# ATSAM4E16C device description
Architecture: CORTEX-M4; Family: SAM4; Series: SAM4E
Registers are 32-bit, read-write, no defined reset value unless marked. A register's access mark holds for its fields unless they carry their own. Offsets are from the block's base; [hi:lo] are bit positions; {n}, {i} and the like mark numbered series.

## ACC — Analog Comparator Controller
Instances: ACC 0x400BC000
0x00 ACC_CR wo — Control Register
  [0] SWRST — SoftWare ReSeT
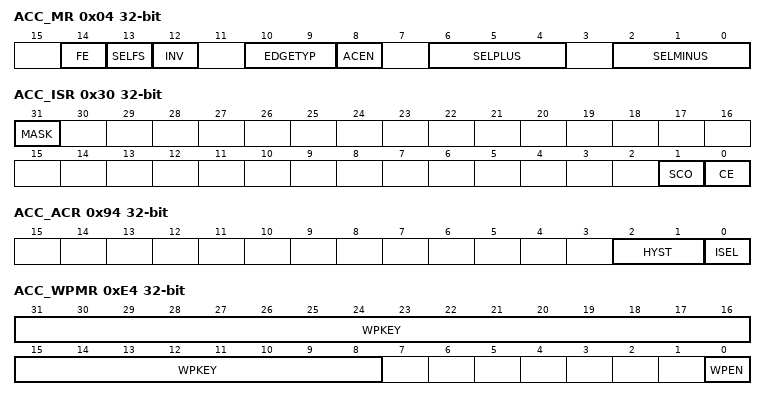
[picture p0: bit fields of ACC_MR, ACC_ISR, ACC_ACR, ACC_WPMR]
0x04 ACC_MR — Mode Register
  [14] FE — Fault Enable
    0=DIS (the FAULT output is tied to 0.); 1=EN (the FAULT output is driven by the signal defined by SELFS.)
  [13] SELFS — SELection of Fault Source
    0=CF (the CF flag is used to drive the FAULT output.); 1=OUTPUT (the output of the Analog Comparator flag is used to drive the FAULT output.)
  [12] INV — INVert comparator output
    0=DIS (Analog Comparator output is directly processed.); 1=EN (Analog Comparator output is inverted prior to being processed.)
  [10:9] EDGETYP — EDGE TYPe
    0=RISING (only rising edge of comparator output); 1=FALLING (falling edge of comparator output); 2=ANY (any edge of comparator output)
  [8] ACEN — Analog Comparator ENable
    0=DIS (Analog Comparator Disabled.); 1=EN (Analog Comparator Enabled.)
  [6:4] SELPLUS — SELection for PLUS comparator input
    {v}=AD{v} (Select AD{v}) (v=0..7)
  [2:0] SELMINUS — SELection for MINUS comparator input
    0=TS (SelectTS); 1=ADVREF (Select ADVREF); 2=DAC0 (Select DAC0); 3=DAC1 (Select DAC1); {v}=AD{v-4} (Select AD{v-4}) (v=4..7)
0x24 ACC_IER wo — Interrupt Enable Register
  [0] CE — Comparison Edge
0x28 ACC_IDR wo — Interrupt Disable Register
  [0] CE — Comparison Edge
0x2C ACC_IMR ro — Interrupt Mask Register
  [0] CE — Comparison Edge
0x30 ACC_ISR ro — Interrupt Status Register
  [31] MASK
  [1] SCO — Synchronized Comparator Output
  [0] CE — Comparison Edge
0x94 ACC_ACR — Analog Control Register
  [2:1] HYST — HYSTeresis selection
  [0] ISEL — Current SELection
    0=LOPW (low power option.); 1=HISP (high speed option.)
0xE4 ACC_WPMR — Write Protect Mode Register
  [31:8] WPKEY — Write Protect KEY
  [0] WPEN — Write Protect Enable
0xE8 ACC_WPSR ro — Write Protect Status Register
  [0] WPROTERR — Write PROTection ERRor

## AES — Advanced Encryption Standard
Instances: AES 0x40004000
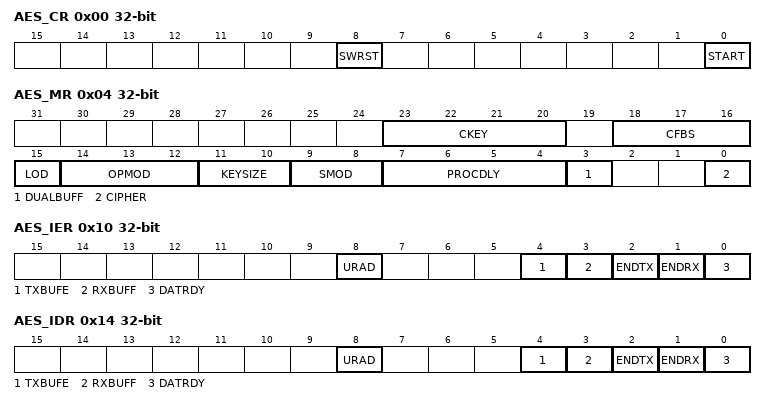
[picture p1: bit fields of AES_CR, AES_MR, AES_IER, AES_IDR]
0x00 AES_CR wo — Control Register
  [8] SWRST — Software Reset
  [0] START — Start Processing
0x04 AES_MR — Mode Register
  [23:20] CKEY — Key
  [18:16] CFBS — Cipher Feedback Data Size
    0=SIZE_128BIT (128-bit); 1=SIZE_64BIT (64-bit); 2=SIZE_32BIT (32-bit); 3=SIZE_16BIT (16-bit); 4=SIZE_8BIT (8-bit)
  [15] LOD — Last Output Data Mode
  [14:12] OPMOD — Operation Mode
    0=ECB (ECB: Electronic Code Book mode); 1=CBC (CBC: Cipher Block Chaining mode); 2=OFB (OFB: Output Feedback mode); 3=CFB (CFB: Cipher Feedback mode); 4=CTR (CTR: Counter mode (16-bit internal counter))
  [11:10] KEYSIZE
    0=AES128 (AES Key Size is 128 bits); 1=AES192 (AES Key Size is 192 bits); 2=AES256 (AES Key Size is 256 bits)
  [9:8] SMOD — Start Mode
    0=MANUAL_START (Manual Mode); 1=AUTO_START (Auto Mode); 2=IDATAR0_START (AES_IDATAR0 access only Auto Mode)
  [7:4] PROCDLY — Processing Delay
  [3] DUALBUFF — Dual Input BUFFer
    0=INACTIVE (AES_IDATARx cannot be written during processing of previous block.); 1=ACTIVE (AES_IDATARx can be written during processing of previous block when SMOD = 0x2. It speeds up the overall runtime of large files.)
  [0] CIPHER — Processing Mode
0x10 AES_IER wo — Interrupt Enable Register
  [8] URAD — Unspecified Register Access Detection Interrupt Enable
  [4] TXBUFE — Transmit Buffer Empty Interrupt Enable
  [3] RXBUFF — Receive Buffer Full Interrupt Enable
  [2] ENDTX — End of Transmit Buffer Interrupt Enable
  [1] ENDRX — End of Receive Buffer Interrupt Enable
  [0] DATRDY — Data Ready Interrupt Enable
0x14 AES_IDR wo — Interrupt Disable Register
  [8] URAD — Unspecified Register Access Detection Interrupt Disable
  [4] TXBUFE — Transmit Buffer Empty Interrupt Disable
  [3] RXBUFF — Receive Buffer Full Interrupt Disable
  [2] ENDTX — End of Transmit Buffer Interrupt Disable
  [1] ENDRX — End of Receive Buffer Interrupt Disable
  [0] DATRDY — Data Ready Interrupt Disable
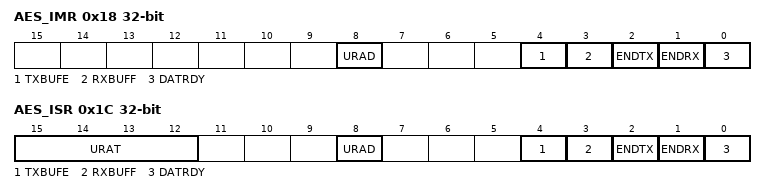
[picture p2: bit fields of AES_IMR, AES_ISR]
0x18 AES_IMR ro — Interrupt Mask Register
  [8] URAD — Unspecified Register Access Detection Interrupt Mask
  [4] TXBUFE — Transmit Buffer Empty Interrupt Mask
  [3] RXBUFF — Receive Buffer Full Interrupt Mask
  [2] ENDTX — End of Transmit Buffer Interrupt Mask
  [1] ENDRX — End of Receive Buffer Interrupt Mask
  [0] DATRDY — Data Ready Interrupt Mask
0x1C AES_ISR ro — Interrupt Status Register
  [15:12] URAT — Unspecified Register Access:
    0=IDR_WR_PROCESSING (Input Data Register written during the data processing when SMOD=0x2 mode.); 1=ODR_RD_PROCESSING (Output Data Register read during the data processing.); 2=MR_WR_PROCESSING (Mode Register written during the data processing.); 3=ODR_RD_SUBKGEN (Output Data Register read during the sub-keys generation.); 4=MR_WR_SUBKGEN (Mode Register written during the sub-keys generation.); 5=WOR_RD_ACCESS (Write-only register read access.)
  [8] URAD — Unspecified Register Access Detection Status
  [4] TXBUFE — TX Buffer Empty
  [3] RXBUFF — RX Buffer Full
  [2] ENDTX — End of TX Buffer
  [1] ENDRX — End of RX Buffer
  [0] DATRDY — Data Ready
{0x20+4i} AES_KEYWR{i} wo (i=0..7) — Key Word Register {i}
  [31:0] KEYW — Key Word
{0x40+4i} AES_IDATAR{i} wo (i=0..3) — Input Data Register {i}
  [31:0] IDATA — Input Data Word
{0x50+4i} AES_ODATAR{i} ro (i=0..3) — Output Data Register {i}
  [31:0] ODATA — Output Data
{0x60+4i} AES_IVR{i} wo (i=0..3) — Initialization Vector Register {i}
  [31:0] IV — Initialization Vector

## Notices in the file
SAM Software Package License
Copyright (c) %copyright_year%, Atmel Corporation
All rights reserved.
Redistribution and use in source and binary forms, with or without
modification, are permitted provided that the following condition is met:
- Redistributions of source code must retain the above copyright notice,
this list of conditions and the disclaimer below.
Atmel's name may not be used to endorse or promote products derived from
this software without specific prior written permission.
DISCLAIMER:  THIS SOFTWARE IS PROVIDED BY ATMEL "AS IS" AND ANY EXPRESS OR
IMPLIED WARRANTIES, INCLUDING, BUT NOT LIMITED TO, THE IMPLIED WARRANTIES OF
MERCHANTABILITY, FITNESS FOR A PARTICULAR PURPOSE AND NON-INFRINGEMENT ARE
DISCLAIMED. IN NO EVENT SHALL ATMEL BE LIABLE FOR ANY DIRECT, INDIRECT,
INCIDENTAL, SPECIAL, EXEMPLARY, OR CONSEQUENTIAL DAMAGES (INCLUDING, BUT NOT
LIMITED TO, PROCUREMENT OF SUBSTITUTE GOODS OR SERVICES; LOSS OF USE, DATA,
OR PROFITS; OR BUSINESS INTERRUPTION) HOWEVER CAUSED AND ON ANY THEORY OF
LIABILITY, WHETHER IN CONTRACT, STRICT LIABILITY, OR TORT (INCLUDING
NEGLIGENCE OR OTHERWISE) ARISING IN ANY WAY OUT OF THE USE OF THIS SOFTWARE,
EVEN IF ADVISED OF THE POSSIBILITY OF SUCH DAMAGE.
